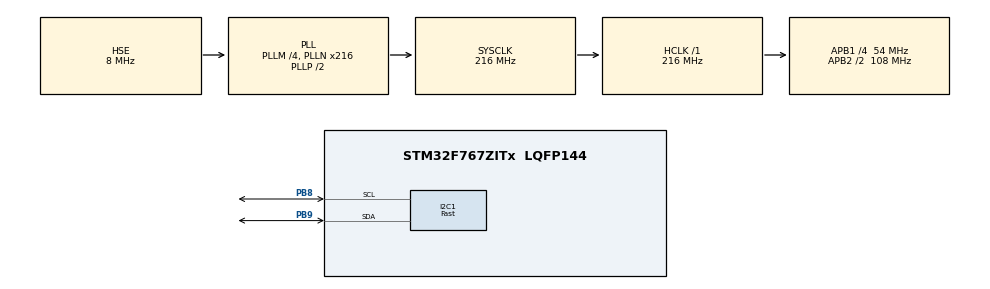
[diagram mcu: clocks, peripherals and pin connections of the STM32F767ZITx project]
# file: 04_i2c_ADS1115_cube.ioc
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I2C1.I2C_Speed_Mode=I2C_Fast
I2C1.Timing=0x6000030D
Mcu.Family=STM32F7
Mcu.Name=STM32F767ZITx
Mcu.Package=LQFP144
NVIC.I2C1_ER_IRQn=true\:0\:0\:false\:false\:true\:true\:true
NVIC.I2C1_EV_IRQn=true\:0\:0\:false\:false\:true\:true\:true
NVIC.PriorityGroup=NVIC_PRIORITYGROUP_4
NVIC.RCC_IRQn=true\:0\:0\:false\:false\:true\:true\:false
PB8.GPIO_Pu=GPIO_NOPULL
PB8.Mode=I2C
PB8.Signal=I2C1_SCL
PB9.GPIO_Pu=GPIO_PULLUP
PB9.Mode=I2C
PB9.Signal=I2C1_SDA
PH0/OSC_IN.Mode=HSE-External-Clock-Source
PH0/OSC_IN.Signal=RCC_OSC_IN
PH1/OSC_OUT.Mode=HSE-External-Clock-Source
PH1/OSC_OUT.Signal=RCC_OSC_OUT
ProjectManager.HeapSize=0x200
ProjectManager.StackSize=0x400
ProjectManager.TargetToolchain=STM32CubeIDE
RCC.AHBFreq_Value=216000000
RCC.APB1CLKDivider=RCC_HCLK_DIV4
RCC.APB1Freq_Value=54000000
RCC.APB1TimFreq_Value=108000000
RCC.APB2CLKDivider=RCC_HCLK_DIV2
RCC.APB2Freq_Value=108000000
RCC.APB2TimFreq_Value=216000000
RCC.CortexFreq_Value=216000000
RCC.EnbaleCSS=true
RCC.HCLKFreq_Value=216000000
RCC.HSE_VALUE=8000000
RCC.HSI_VALUE=16000000
RCC.LSE_VALUE=32768
RCC.PLLM=4
RCC.PLLN=216
RCC.PLLSourceVirtual=RCC_PLLSOURCE_HSE
RCC.SYSCLKFreq_VALUE=216000000
RCC.SYSCLKSource=RCC_SYSCLKSOURCE_PLLCLK
RCC.USBFreq_Value=216000000
RCC.VCOOutputFreq_Value=432000000
board=custom

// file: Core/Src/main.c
/* USER CODE BEGIN Header */
/**
  ******************************************************************************
  * @file           : main.c
  * @brief          : Main program body
  ******************************************************************************
  * @attention
  *
  * Copyright (c) 2021 STMicroelectronics.
  * All rights reserved.
  *
  * This software is licensed under terms that can be found in the LICENSE file
  * in the root directory of this software component.
  * If no LICENSE file comes with this software, it is provided AS-IS.
  *
  ******************************************************************************
  */
/* USER CODE END Header */
#include "main.h"

/* USER CODE BEGIN PTD */
#define ADS1115_ADDRESS 0x48

uint8_t config[3];
uint8_t conv_data[1];
uint8_t read_data[2];
uint16_t reading;
float voltage[4];
const float voltageConv = 2.048 / 32768.0;
/* USER CODE END PTD */

I2C_HandleTypeDef hi2c1;

void SystemClock_Config(void);
static void MX_GPIO_Init(void);
static void MX_I2C1_Init(void);

int main(void)
{

  /* MCU Configuration--------------------------------------------------------*/

  /* Reset of all peripherals, Initializes the Flash interface and the Systick. */
  HAL_Init();

  /* Configure the system clock */
  SystemClock_Config();

  /* Initialize all configured peripherals */
  MX_GPIO_Init();
  MX_I2C1_Init();

  /* Infinite loop */
  /* USER CODE BEGIN WHILE */
  while (1)
  {
	  for(int i=0; i< 4; i++){
	  			config[0] = 0x01;  // this means we are writing to the config register.

	  			switch(i){
	  				case(0):
	  					config[1] = 0xC5; // [OS = 1] [MUX = 100] [PGA = 010] [MODE = 1]    channel 0 = 11000101 = 0xC5
	  				break;
	  				case(1):
	  					config[1] = 0xD5; // [OS = 1] [MUX = 101] [PGA = 010] [MODE = 1]    channel 1
	  				break;
	  				case(2):
	  					config[1] = 0xE5; // [OS = 1] [MUX = 110] [PGA = 010] [MODE = 1]    channel 2
	  				break;
	  				case(3):
	  					config[1] = 0xF5;  // [OS = 1] [MUX = 111] [PGA = 010] [MODE = 1]    channel 3
	  				break;
	  			}

	  			config[2] = 0x83; // [DR = 100] [COMP_MODE = 0] [COMP_POLL = 0] [COMP_LAT = 0] [COMP_QUE = 11]

	  			// comparator is used to set the ALERT ready pin which we dont really need.

	  			HAL_I2C_Master_Transmit(&hi2c1, ADS1115_ADDRESS << 1, config, 3, 100); //
	  			// the address shift is done because it is mentioned in the HAL_I2C specs, i dont know exactly why ?
	  			// but the HAL_I2C_Master_Transmit specifications say that it should be left shifted by 1 bit.

	  			conv_data[0] = 0x00; // steps for reading conversion register now.

	  			HAL_I2C_Master_Transmit(&hi2c1, ADS1115_ADDRESS << 1 , conv_data, 1 ,100);
	  			HAL_Delay(20);

	  			HAL_I2C_Master_Receive(&hi2c1, ADS1115_ADDRESS <<1, read_data, 2, 100);
	  			reading = (read_data[0] << 8 | read_data[1] );
	  			if(reading < 0) {
	  				reading = 0;
	  			}
	  			voltage[i] = reading * voltageConv;

	  		}
	  HAL_Delay(1000);
    /* USER CODE END WHILE */

  }
}

void SystemClock_Config(void)
{
  RCC_OscInitTypeDef RCC_OscInitStruct = {0};
  RCC_ClkInitTypeDef RCC_ClkInitStruct = {0};

  /** Configure the main internal regulator output voltage
  */
  __HAL_RCC_PWR_CLK_ENABLE();
  __HAL_PWR_VOLTAGESCALING_CONFIG(PWR_REGULATOR_VOLTAGE_SCALE1);
  /** Initializes the RCC Oscillators according to the specified parameters
  * in the RCC_OscInitTypeDef structure.
  */
  RCC_OscInitStruct.OscillatorType = RCC_OSCILLATORTYPE_HSE;
  RCC_OscInitStruct.HSEState = RCC_HSE_BYPASS;
  RCC_OscInitStruct.PLL.PLLState = RCC_PLL_ON;
  RCC_OscInitStruct.PLL.PLLSource = RCC_PLLSOURCE_HSE;
  RCC_OscInitStruct.PLL.PLLM = 4;
  RCC_OscInitStruct.PLL.PLLN = 216;
  RCC_OscInitStruct.PLL.PLLP = RCC_PLLP_DIV2;
  RCC_OscInitStruct.PLL.PLLQ = 2;
  RCC_OscInitStruct.PLL.PLLR = 2;
  if (HAL_RCC_OscConfig(&RCC_OscInitStruct) != HAL_OK)
  {
    Error_Handler();
  }
  /** Activate the Over-Drive mode
  */
  if (HAL_PWREx_EnableOverDrive() != HAL_OK)
  {
    Error_Handler();
  }
  /** Initializes the CPU, AHB and APB buses clocks
  */
  RCC_ClkInitStruct.ClockType = RCC_CLOCKTYPE_HCLK|RCC_CLOCKTYPE_SYSCLK
                              |RCC_CLOCKTYPE_PCLK1|RCC_CLOCKTYPE_PCLK2;
  RCC_ClkInitStruct.SYSCLKSource = RCC_SYSCLKSOURCE_PLLCLK;
  RCC_ClkInitStruct.AHBCLKDivider = RCC_SYSCLK_DIV1;
  RCC_ClkInitStruct.APB1CLKDivider = RCC_HCLK_DIV4;
  RCC_ClkInitStruct.APB2CLKDivider = RCC_HCLK_DIV2;

  if (HAL_RCC_ClockConfig(&RCC_ClkInitStruct, FLASH_LATENCY_7) != HAL_OK)
  {
    Error_Handler();
  }
  /** Enables the Clock Security System
  */
  HAL_RCC_EnableCSS();
}

static void MX_I2C1_Init(void)
{

  hi2c1.Instance = I2C1;
  hi2c1.Init.Timing = 0x6000030D;
  hi2c1.Init.OwnAddress1 = 0;
  hi2c1.Init.AddressingMode = I2C_ADDRESSINGMODE_7BIT;
  hi2c1.Init.DualAddressMode = I2C_DUALADDRESS_DISABLE;
  hi2c1.Init.OwnAddress2 = 0;
  hi2c1.Init.OwnAddress2Masks = I2C_OA2_NOMASK;
  hi2c1.Init.GeneralCallMode = I2C_GENERALCALL_DISABLE;
  hi2c1.Init.NoStretchMode = I2C_NOSTRETCH_DISABLE;
  if (HAL_I2C_Init(&hi2c1) != HAL_OK)
  {
    Error_Handler();
  }
  /** Configure Analogue filter
  */
  if (HAL_I2CEx_ConfigAnalogFilter(&hi2c1, I2C_ANALOGFILTER_ENABLE) != HAL_OK)
  {
    Error_Handler();
  }
  /** Configure Digital filter
  */
  if (HAL_I2CEx_ConfigDigitalFilter(&hi2c1, 0) != HAL_OK)
  {
    Error_Handler();
  }

}

static void MX_GPIO_Init(void)
{

  /* GPIO Ports Clock Enable */
  __HAL_RCC_GPIOH_CLK_ENABLE();
  __HAL_RCC_GPIOB_CLK_ENABLE();

}

void Error_Handler(void)
{
  __disable_irq();
  while (1)
  {
  }
}
